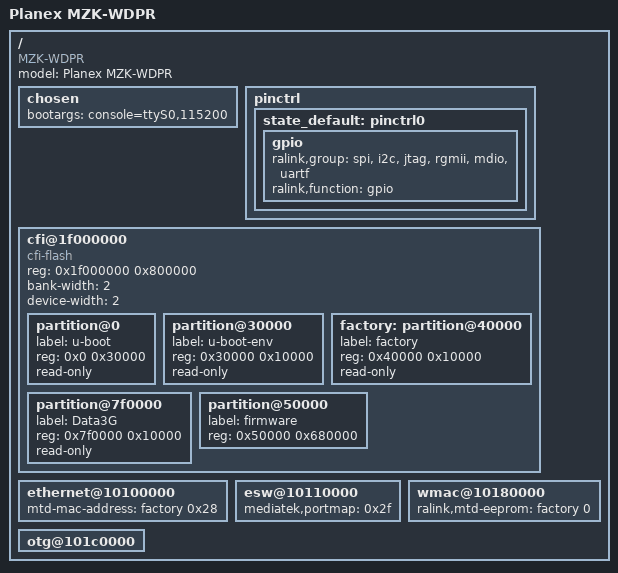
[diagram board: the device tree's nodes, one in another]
/dts-v1/;

/include/ "rt3050.dtsi"

/ {
	compatible = "MZK-WDPR", "ralink,rt3052-soc";
	model = "Planex MZK-WDPR";

	chosen {
		bootargs = "console=ttyS0,115200";
	};

	pinctrl {
		state_default: pinctrl0 {
			gpio {
				ralink,group = "spi", "i2c", "jtag", "rgmii", "mdio", "uartf";
				ralink,function = "gpio";
			};
		};
	};

	cfi@1f000000 {
		compatible = "cfi-flash";
		reg = <0x1f000000 0x800000>;

		bank-width = <2>;
		device-width = <2>;
		#address-cells = <1>;
		#size-cells = <1>;

		partition@0 {
			label = "u-boot";
			reg = <0x0 0x30000>;
			read-only;
		};

		partition@30000 {
			label = "u-boot-env";
			reg = <0x30000 0x10000>;
			read-only;
		};

		factory: partition@40000 {
			label = "factory";
			reg = <0x40000 0x10000>;
			read-only;
		};

		partition@7f0000 {
			label = "Data3G";
			reg = <0x7f0000 0x10000>;
			read-only;
		};

		partition@50000 {
			label = "firmware";
			reg = <0x50000 0x680000>;
		};
	};

	ethernet@10100000 {
		mtd-mac-address = <&factory 0x28>;
	};

	esw@10110000 {
		mediatek,portmap = <0x2f>;
	};

	wmac@10180000 {
		ralink,mtd-eeprom = <&factory 0>;
	};

	otg@101c0000 {
		status = "okay";
	};
};
